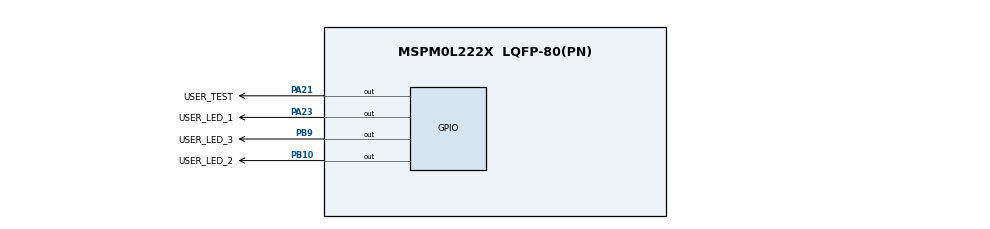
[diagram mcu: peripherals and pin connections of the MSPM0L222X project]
/**
 *
 * @cliArgs --device "MSPM0L222X" --part "Default" --package "LQFP-80(PN)" --product "mspm0_sdk@2.11.00.07"
 * @versions {"tool":"1.28.1+4785"}
 */

/**
 * Import the modules used in this configuration.
 */
const GPIO          = scripting.addModule("/ti/driverlib/GPIO", {}, false);
const GPIO1         = GPIO.addInstance();
const SYSCTL        = scripting.addModule("/ti/driverlib/SYSCTL");
const UART          = scripting.addModule("/ti/driverlib/UART", {}, false);
const UART1         = UART.addInstance();
const ProjectConfig = scripting.addModule("/ti/project_config/ProjectConfig");

/**
 * Write custom configuration values to the imported modules.
 */
GPIO1.$name                         = "GPIO_LEDS";
GPIO1.associatedPins.create(4);
GPIO1.associatedPins[0].$name       = "USER_LED_1";
GPIO1.associatedPins[0].pin.$assign = "PA23";
GPIO1.associatedPins[1].$name       = "USER_LED_2";
GPIO1.associatedPins[1].pin.$assign = "PB10";
GPIO1.associatedPins[2].$name       = "USER_LED_3";
GPIO1.associatedPins[2].pin.$assign = "PB9";
GPIO1.associatedPins[3].$name       = "USER_TEST";
GPIO1.associatedPins[3].pin.$assign = "PA21";

const Board = scripting.addModule("/ti/driverlib/Board", {}, false);

SYSCTL.clockTreeEn           = true;
SYSCTL.forceDefaultClkConfig = true;

UART1.$name              = "UART_0";
UART1.flowControl        = "RTS_CTS";
UART1.targetBaudRate     = 115200;
UART1.txPinConfig.$name  = "ti_driverlib_gpio_GPIOPinGeneric0";
UART1.rxPinConfig.$name  = "ti_driverlib_gpio_GPIOPinGeneric1";
UART1.rtsPinConfig.$name = "ti_driverlib_gpio_GPIOPinGeneric2";
UART1.ctsPinConfig.$name = "ti_driverlib_gpio_GPIOPinGeneric3";

ProjectConfig.genLinker = false;

/**
 * Pinmux solution for unlocked pins/peripherals. This ensures that minor changes to the automatic solver in a future
 * version of the tool will not impact the pinmux you originally saw.  These lines can be completely deleted in order to
 * re-solve from scratch.
 */
Board.peripheral.$suggestSolution          = "DEBUGSS";
Board.peripheral.swclkPin.$suggestSolution = "PA20";
Board.peripheral.swdioPin.$suggestSolution = "PA19";
UART1.peripheral.$suggestSolution          = "UART0";
UART1.peripheral.rxPin.$suggestSolution    = "PA1";
UART1.peripheral.txPin.$suggestSolution    = "PA0";
UART1.peripheral.rtsPin.$suggestSolution   = "PA15";
UART1.peripheral.ctsPin.$suggestSolution   = "PA14";
